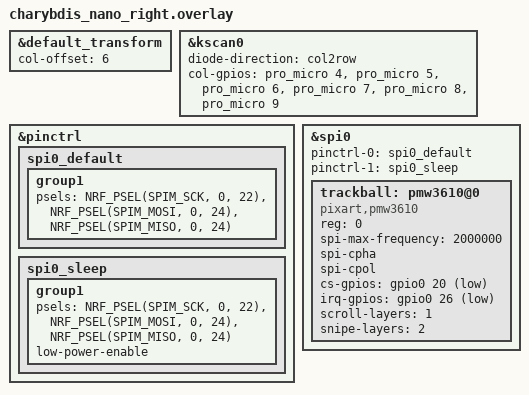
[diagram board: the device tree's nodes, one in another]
 
#include "charybdis_nano.dtsi"
#include <zephyr/dt-bindings/pinctrl/nrf-pinctrl.h>

&default_transform {
    col-offset = <6>;
};

&kscan0 {
    diode-direction = "col2row";
    col-gpios
        = <&pro_micro 4 (GPIO_ACTIVE_HIGH)> // COL0 
        , <&pro_micro 5 (GPIO_ACTIVE_HIGH)> // COL1 
        , <&pro_micro 6 (GPIO_ACTIVE_HIGH)> // COL2 
        , <&pro_micro 7 (GPIO_ACTIVE_HIGH)> // COL3 
        , <&pro_micro 8 (GPIO_ACTIVE_HIGH)> // COL1 
        , <&pro_micro 9 (GPIO_ACTIVE_HIGH)> // COL2 
    ;
    
};

&pinctrl {
    spi0_default: spi0_default {
        group1 {
            psels = <NRF_PSEL(SPIM_SCK, 0, 22)>,
                <NRF_PSEL(SPIM_MOSI, 0, 24)>,
                <NRF_PSEL(SPIM_MISO, 0, 24)>;
        };
    };

    spi0_sleep: spi0_sleep {
        group1 {
            psels = <NRF_PSEL(SPIM_SCK, 0, 22)>,
                <NRF_PSEL(SPIM_MOSI, 0, 24)>,
                <NRF_PSEL(SPIM_MISO, 0, 24)>;
            low-power-enable;
        };
    };
};

&spi0 {
    status = "okay";
    pinctrl-0 = <&spi0_default>;
    pinctrl-1 = <&spi0_sleep>;
    pinctrl-names = "default", "sleep";

    trackball: pmw3610@0 {
        status = "okay";
        compatible = "pixart,pmw3610";
        reg = <0>;
        spi-max-frequency = <2000000>;
        spi-cpha;                          // SPI Mode 3
        spi-cpol;                          // SPI Mode 3
        
        cs-gpios = <&gpio0 20 GPIO_ACTIVE_LOW>;
        irq-gpios = <&gpio0 26 GPIO_ACTIVE_LOW>;
        
        scroll-layers = <1>;
        snipe-layers = <2>;
        // automouse-layer = <3>;
    };
};
